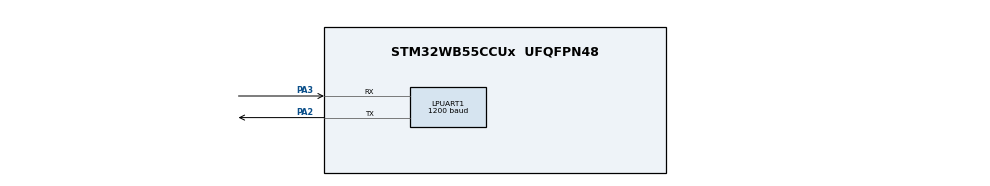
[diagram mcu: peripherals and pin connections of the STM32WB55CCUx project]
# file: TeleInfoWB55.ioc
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LPUART1.BaudRate=1200
LPUART1.Parity=UART_PARITY_EVEN
LPUART1.WordLength=UART_WORDLENGTH_8B
Mcu.Family=STM32WB
Mcu.Name=STM32WB55CCUx
Mcu.Package=UFQFPN48
NVIC.HSEM_IRQn=true\:0\:0\:false\:false\:true\:false\:true
NVIC.LPUART1_IRQn=true\:0\:0\:false\:false\:true\:true\:true
NVIC.PriorityGroup=NVIC_PRIORITYGROUP_4
OSC_IN.Mode=HSE-External-Oscillator
OSC_IN.Signal=RCC_OSC_IN
OSC_OUT.Mode=HSE-External-Oscillator
OSC_OUT.Signal=RCC_OSC_OUT
PA13.Mode=Serial_Wire
PA13.Signal=SYS_JTMS-SWDIO
PA14.Mode=Serial_Wire
PA14.Signal=SYS_JTCK-SWCLK
PA2.Mode=Asynchronous
PA2.Signal=LPUART1_TX
PA3.Mode=Asynchronous
PA3.Signal=LPUART1_RX
PC14-OSC32_IN.Mode=LSE-External-Oscillator
PC14-OSC32_IN.Signal=RCC_OSC32_IN
PC15-OSC32_OUT.Mode=LSE-External-Oscillator
PC15-OSC32_OUT.Signal=RCC_OSC32_OUT
ProjectManager.HeapSize=0x200
ProjectManager.StackSize=0x400
ProjectManager.TargetToolchain=STM32CubeIDE
RCC.ADCFreq_Value=128000000
RCC.AHBFreq_Value=32000000
RCC.APB1CLKDivider=RCC_HCLK_DIV8
RCC.APB1Freq_Value=4000000
RCC.APB1TimFreq_Value=8000000
RCC.APB2Freq_Value=32000000
RCC.APB2TimFreq_Value=32000000
RCC.APB3Freq_Value=16000000
RCC.CortexFreq_Value=32000000
RCC.HCLKFreq_Value=32000000
RCC.HSE_VALUE=32000000
RCC.HSI48_VALUE=48000000
RCC.HSI_VALUE=16000000
RCC.MSIClockRange=RCC_MSIRANGE_10
RCC.SYSCLKFreq_VALUE=32000000
RCC.USBFreq_Value=128000000
RCC.VCOOutputFreq_Value=256000000
RF1.Mode=RF1_Activate
RF1.Signal=RF_RF1
STM32_WPAN.CB_ELECTRICALMEASUREMENT_SERVER_GETMEASUREPROFILE_ENDPOINT1=false
STM32_WPAN.CB_ELECTRICALMEASUREMENT_SERVER_GETPROFILEINFO_ENDPOINT1=false
STM32_WPAN.ENDPOINT1_DEVICE_ID=ZCL_DEVICE_METER_INTERFACE
STM32_WPAN.ENDPOINT1_ID_ZGB=1
STM32_WPAN.ZCL_ELECTRICALMEASUREMENT_ENDPOINT1=SERVER
VP_HSEM_VS_HSEM.Mode=HSEM_Activate
VP_IPCC_VS_IPCC.Mode=IPCC_Activate
VP_RTC_VS_RTC_Activate.Mode=RTC_Enabled
VP_SEQUENCER_VS_SEQUENCER.Mode=SEQUENCER_Enabled
VP_STM32_WPAN_VS_ZIGBEE.Mode=MOD_ZGB_ENDPOINT
VP_TINY_LPM_VS_TINY_LPM.Mode=TINY_LPM_Enabled
board=custom

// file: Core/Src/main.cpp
/* USER CODE BEGIN Header */
/**
  ******************************************************************************
  * @file           : main.c
  * @brief          : Main program body
  ******************************************************************************
  * @attention
  *
  * <h2><center>&copy; Copyright (c) 2021 STMicroelectronics.
  * All rights reserved.</center></h2>
  *
  * This software component is licensed by ST under BSD 3-Clause license,
  * the "License"; You may not use this file except in compliance with the
  * License. You may obtain a copy of the License at:
  *                        opensource.org/licenses/BSD-3-Clause
  *
  ******************************************************************************
  */
/* USER CODE END Header */
#include "main.h"

/* USER CODE BEGIN Includes */
#include "LibTeleinfo.hpp"
#include "app_zigbee.h"
/* USER CODE END Includes */

IPCC_HandleTypeDef hipcc;

UART_HandleTypeDef hlpuart1;

RTC_HandleTypeDef hrtc;

void SystemClock_Config(void);
static void MX_GPIO_Init(void);
static void MX_IPCC_Init(void);
static void MX_LPUART1_UART_Init(void);
static void MX_RF_Init(void);
static void MX_RTC_Init(void);
/* USER CODE BEGIN PFP */
void TeleInfo_Data(ValueList *valueslist, uint8_t state);
/* USER CODE END PFP */

/* USER CODE BEGIN 0 */
TInfo _tinfo;
char dataUART;
/* USER CODE END 0 */

int main(void)
{

  /* MCU Configuration--------------------------------------------------------*/

  /* Reset of all peripherals, Initializes the Flash interface and the Systick. */
  HAL_Init();
  /* Config code for STM32_WPAN (HSE Tuning must be done before system clock configuration) */
  MX_APPE_Config();

  /* Configure the system clock */
  SystemClock_Config();

  /* IPCC initialisation */
   MX_IPCC_Init();

  /* Initialize all configured peripherals */
  MX_GPIO_Init();
  MX_LPUART1_UART_Init();
  MX_RF_Init();
  MX_RTC_Init();

  /* Init code for STM32_WPAN */
  MX_APPE_Init();
  /* Infinite loop */
  /* USER CODE BEGIN WHILE */
  uint32_t last, now;

  _tinfo.init();
  _tinfo.attachData(&TeleInfo_Data);
  last = HAL_GetTick();
  while (1)
  {
    /* USER CODE END WHILE */
    MX_APPE_Process();

  }
}

void SystemClock_Config(void)
{
  RCC_OscInitTypeDef RCC_OscInitStruct = {0};
  RCC_ClkInitTypeDef RCC_ClkInitStruct = {0};
  RCC_PeriphCLKInitTypeDef PeriphClkInitStruct = {0};

  /** Configure the main internal regulator output voltage
  */
  __HAL_PWR_VOLTAGESCALING_CONFIG(PWR_REGULATOR_VOLTAGE_SCALE1);
  /** Initializes the RCC Oscillators according to the specified parameters
  * in the RCC_OscInitTypeDef structure.
  */
  RCC_OscInitStruct.OscillatorType = RCC_OSCILLATORTYPE_HSI|RCC_OSCILLATORTYPE_LSI1
                              |RCC_OSCILLATORTYPE_HSE|RCC_OSCILLATORTYPE_MSI;
  RCC_OscInitStruct.HSEState = RCC_HSE_ON;
  RCC_OscInitStruct.HSIState = RCC_HSI_ON;
  RCC_OscInitStruct.MSIState = RCC_MSI_ON;
  RCC_OscInitStruct.HSICalibrationValue = RCC_HSICALIBRATION_DEFAULT;
  RCC_OscInitStruct.MSICalibrationValue = RCC_MSICALIBRATION_DEFAULT;
  RCC_OscInitStruct.MSIClockRange = RCC_MSIRANGE_10;
  RCC_OscInitStruct.LSIState = RCC_LSI_ON;
  RCC_OscInitStruct.PLL.PLLState = RCC_PLL_NONE;
  if (HAL_RCC_OscConfig(&RCC_OscInitStruct) != HAL_OK)
  {
    Error_Handler();
  }
  /** Configure the SYSCLKSource, HCLK, PCLK1 and PCLK2 clocks dividers
  */
  RCC_ClkInitStruct.ClockType = RCC_CLOCKTYPE_HCLK4|RCC_CLOCKTYPE_HCLK2
                              |RCC_CLOCKTYPE_HCLK|RCC_CLOCKTYPE_SYSCLK
                              |RCC_CLOCKTYPE_PCLK1|RCC_CLOCKTYPE_PCLK2;
  RCC_ClkInitStruct.SYSCLKSource = RCC_SYSCLKSOURCE_MSI;
  RCC_ClkInitStruct.AHBCLKDivider = RCC_SYSCLK_DIV1;
  RCC_ClkInitStruct.APB1CLKDivider = RCC_HCLK_DIV8;
  RCC_ClkInitStruct.APB2CLKDivider = RCC_HCLK_DIV1;
  RCC_ClkInitStruct.AHBCLK2Divider = RCC_SYSCLK_DIV1;
  RCC_ClkInitStruct.AHBCLK4Divider = RCC_SYSCLK_DIV1;

  if (HAL_RCC_ClockConfig(&RCC_ClkInitStruct, FLASH_LATENCY_1) != HAL_OK)
  {
    Error_Handler();
  }
  /** Initializes the peripherals clocks
  */
  PeriphClkInitStruct.PeriphClockSelection = RCC_PERIPHCLK_SMPS|RCC_PERIPHCLK_RFWAKEUP
                              |RCC_PERIPHCLK_RTC|RCC_PERIPHCLK_LPUART1;
  PeriphClkInitStruct.Lpuart1ClockSelection = RCC_LPUART1CLKSOURCE_PCLK1;
  PeriphClkInitStruct.RTCClockSelection = RCC_RTCCLKSOURCE_LSI;
  PeriphClkInitStruct.RFWakeUpClockSelection = RCC_RFWKPCLKSOURCE_HSE_DIV1024;
  PeriphClkInitStruct.SmpsClockSelection = RCC_SMPSCLKSOURCE_HSI;
  PeriphClkInitStruct.SmpsDivSelection = RCC_SMPSCLKDIV_RANGE1;
  if (HAL_RCCEx_PeriphCLKConfig(&PeriphClkInitStruct) != HAL_OK)
  {
    Error_Handler();
  }
}

static void MX_IPCC_Init(void)
{

  hipcc.Instance = IPCC;
  if (HAL_IPCC_Init(&hipcc) != HAL_OK)
  {
    Error_Handler();
  }

}

static void MX_LPUART1_UART_Init(void)
{

  hlpuart1.Instance = LPUART1;
  hlpuart1.Init.BaudRate = 1200;
  hlpuart1.Init.WordLength = UART_WORDLENGTH_8B;
  hlpuart1.Init.StopBits = UART_STOPBITS_1;
  hlpuart1.Init.Parity = UART_PARITY_EVEN;
  hlpuart1.Init.Mode = UART_MODE_TX_RX;
  hlpuart1.Init.HwFlowCtl = UART_HWCONTROL_NONE;
  hlpuart1.Init.OneBitSampling = UART_ONE_BIT_SAMPLE_DISABLE;
  hlpuart1.Init.ClockPrescaler = UART_PRESCALER_DIV1;
  hlpuart1.AdvancedInit.AdvFeatureInit = UART_ADVFEATURE_NO_INIT;
  hlpuart1.FifoMode = UART_FIFOMODE_DISABLE;
  if (HAL_UART_Init(&hlpuart1) != HAL_OK)
  {
    Error_Handler();
  }
  if (HAL_UARTEx_SetTxFifoThreshold(&hlpuart1, UART_TXFIFO_THRESHOLD_1_8) != HAL_OK)
  {
    Error_Handler();
  }
  if (HAL_UARTEx_SetRxFifoThreshold(&hlpuart1, UART_RXFIFO_THRESHOLD_1_8) != HAL_OK)
  {
    Error_Handler();
  }
  if (HAL_UARTEx_DisableFifoMode(&hlpuart1) != HAL_OK)
  {
    Error_Handler();
  }

}

static void MX_RF_Init(void)
{

}

static void MX_RTC_Init(void)
{

  /** Initialize RTC Only
  */
  hrtc.Instance = RTC;
  hrtc.Init.HourFormat = RTC_HOURFORMAT_24;
  hrtc.Init.AsynchPrediv = CFG_RTC_ASYNCH_PRESCALER;
  hrtc.Init.SynchPrediv = CFG_RTC_SYNCH_PRESCALER;
  hrtc.Init.OutPut = RTC_OUTPUT_DISABLE;
  hrtc.Init.OutPutPolarity = RTC_OUTPUT_POLARITY_HIGH;
  hrtc.Init.OutPutType = RTC_OUTPUT_TYPE_OPENDRAIN;
  hrtc.Init.OutPutRemap = RTC_OUTPUT_REMAP_NONE;
  if (HAL_RTC_Init(&hrtc) != HAL_OK)
  {
    Error_Handler();
  }

}

static void MX_GPIO_Init(void)
{

  /* GPIO Ports Clock Enable */
  __HAL_RCC_GPIOC_CLK_ENABLE();
  __HAL_RCC_GPIOA_CLK_ENABLE();

}

/* USER CODE BEGIN 4 */
void TeleInfo_Data(ValueList *valueslist, uint8_t state) {

	if (strcmp(valueslist->name, "PAPP") == 0) {
		int zz = atoi(valueslist->value);
		uint16_t  val = (uint16_t) zz ;
		APP_ZIGBEE_TeleInfo_ApparentPower(val);
	} else if (strcmp(valueslist->name, "IMAX") == 0) {
		int zz = atoi(valueslist->value);
		uint16_t  val = (uint16_t) zz ;
		APP_ZIGBEE_TeleInfo_CurrentMax(val);
	}else  if (strcmp(valueslist->name, "IINST") == 0) {
		int zz = atoi(valueslist->value);
		uint16_t  val = (uint16_t) zz ;
		APP_ZIGBEE_TeleInfo_Current(val);
	}else  if (strcmp(valueslist->name, "BASE") == 0) {
		long zz = atol(valueslist->value);
		uint32_t  val = (uint32_t) zz;
		APP_ZIGBEE_TeleInfo_TotalActivePower(val);
	}

}

#ifdef __cplusplus
extern "C" {
#endif
void HAL_UART_RxCpltCallback(UART_HandleTypeDef *huart)
{
  if (huart->Instance == LPUART1)
  {
    _tinfo.process(dataUART);
    HAL_UART_Receive_IT(&hlpuart1, (uint8_t*) &dataUART, 1);
  }
}
#ifdef __cplusplus
}
#endif

/* USER CODE END 4 */

void Error_Handler(void)
{
  __disable_irq();
  while (1)
  {
  }
}

/************************ (C) COPYRIGHT STMicroelectronics *****END OF FILE****/
